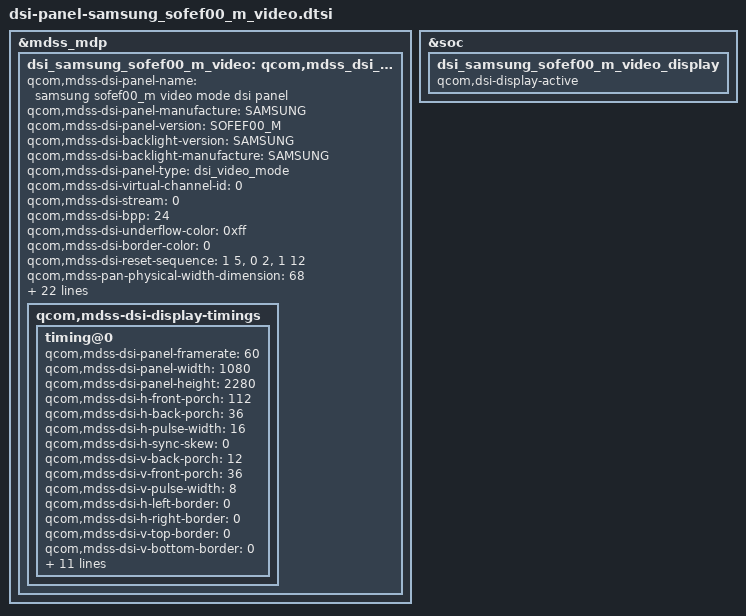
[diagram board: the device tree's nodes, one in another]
/* Copyright (c) 2015-2017, The Linux Foundation. All rights reserved.
 *
 * This program is free software; you can redistribute it and/or modify
 * it under the terms of the GNU General Public License version 2 and
 * only version 2 as published by the Free Software Foundation.
 *
 * This program is distributed in the hope that it will be useful,
 * but WITHOUT ANY WARRANTY; without even the implied warranty of
 * MERCHANTABILITY or FITNESS FOR A PARTICULAR PURPOSE.  See the
 * GNU General Public License for more details.
 */

&mdss_mdp {
	dsi_samsung_sofef00_m_video: qcom,mdss_dsi_samsung_sofef00_m_video {
		qcom,mdss-dsi-panel-name =
		"samsung sofef00_m video mode dsi panel";
		qcom,mdss-dsi-panel-manufacture = "SAMSUNG";
		qcom,mdss-dsi-panel-version = "SOFEF00_M";
		qcom,mdss-dsi-backlight-version = "SAMSUNG";
		qcom,mdss-dsi-backlight-manufacture = "SAMSUNG";
		qcom,mdss-dsi-panel-type = "dsi_video_mode";
		qcom,mdss-dsi-virtual-channel-id = <0>;
		qcom,mdss-dsi-stream = <0>;
		qcom,mdss-dsi-bpp = <24>;
		qcom,mdss-dsi-underflow-color = <0xff>;
		qcom,mdss-dsi-border-color = <0>;
		qcom,mdss-dsi-reset-sequence = <1 5>, <0 2>, <1 12>;
		qcom,mdss-pan-physical-width-dimension = <68>;
		qcom,mdss-pan-physical-height-dimension = <145>;
		qcom,mdss-dsi-traffic-mode = "burst_mode";
		qcom,mdss-dsi-bllp-eof-power-mode;
		qcom,mdss-dsi-bllp-power-mode;
		qcom,mdss-dsi-lane-0-state;
		qcom,mdss-dsi-lane-1-state;
		qcom,mdss-dsi-lane-2-state;
		qcom,mdss-dsi-lane-3-state;
		qcom,mdss-dsi-dma-trigger = "trigger_sw";
		qcom,mdss-dsi-mdp-trigger = "none";
		qcom,mdss-dsi-lp11-init;
	  qcom,mdss-dsi-high-brightness-panel;
		qcom,mdss-bl-high2bit;
		qcom,mdss-dsi-display-timings {
			timing@0{
				qcom,mdss-dsi-panel-framerate = <60>;
				qcom,mdss-dsi-panel-width = <1080>;
				qcom,mdss-dsi-panel-height = <2280>;
				qcom,mdss-dsi-h-front-porch = <112>;
				qcom,mdss-dsi-h-back-porch = <36>;
				qcom,mdss-dsi-h-pulse-width = <16>;
				qcom,mdss-dsi-h-sync-skew = <0>;
				qcom,mdss-dsi-v-back-porch = <12>;
				qcom,mdss-dsi-v-front-porch = <36>;
				qcom,mdss-dsi-v-pulse-width = <8>;
				qcom,mdss-dsi-h-left-border = <0>;
				qcom,mdss-dsi-h-right-border = <0>;
				qcom,mdss-dsi-v-top-border = <0>;
				qcom,mdss-dsi-v-bottom-border = <0>;
				qcom,mdss-dsi-on-command = [
						05 01 00 00 0A 00 02 11 00
						39 01 00 00 00 00 03 F0 5A 5A
						15 01 00 00 00 00 02 35 00
						39 01 00 00 00 00 03 F0 A5 A5
						15 01 00 00 00 00 02 53 20
						15 01 00 00 00 00 02 55 00
					];
				qcom,mdss-dsi-off-command = [
					05 01 00 00 28 00 02 28 00
					05 01 00 00 A0 00 02 10 00
					];
				qcom,mdss-dsi-on-command-state = "dsi_lp_mode";
				qcom,mdss-dsi-off-command-state = "dsi_hs_mode";
				qcom,mdss-dsi-h-sync-pulse = <0>;
				};
		};
	};
};

&dsi_samsung_sofef00_m_video {
	qcom,panel-supply-entries = <&dsi_panel_pwr_supply>;
	qcom,mdss-dsi-bl-pmic-control-type = "bl_ctrl_dcs";
	qcom,mdss-dsi-bl-min-level = <1>;
	qcom,mdss-dsi-bl-max-level = <1023>;
	qcom,platform-te-gpio = <&tlmm 8 0>;
	qcom,platform-reset-gpio = <&tlmm 6 0>;
	qcom,platform-reset-gpio-tmo = <&tlmm 78 0>;
};

&soc {
	dsi_samsung_sofef00_m_video_display {
		qcom,dsi-display-active;
	};
};

&dsi_samsung_sofef00_m_video {
	qcom,mdss-dsi-display-timings {
		timing@0{
			qcom,mdss-dsi-panel-phy-timings = [00 20 07 07 0c 12 06
				08 06 03 04 00];
			qcom,display-topology = <1 0 1>;
			qcom,default-topology-index = <0>;
		};
	};
};
